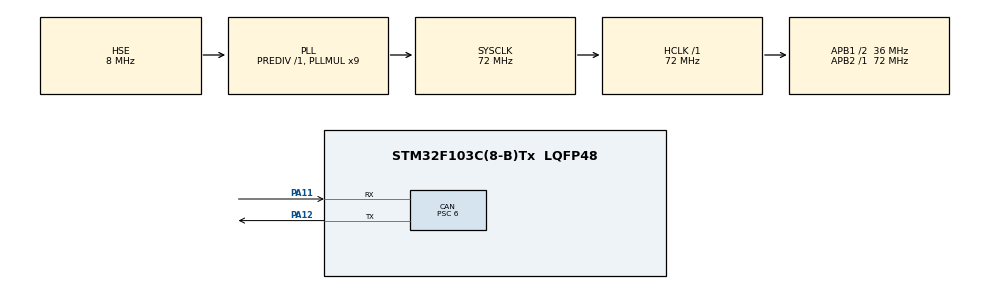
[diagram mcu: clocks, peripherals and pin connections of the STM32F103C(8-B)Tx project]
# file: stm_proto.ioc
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Mcu.Family=STM32F1
RCC.PLLSourceVirtual=RCC_PLLSOURCE_HSE
NVIC.CAN1_RX1_IRQn=true\:0\:0\:false\:true\:true\:4\:true\:true
TIM4.AutoReloadPreload=TIM_AUTORELOAD_PRELOAD_ENABLE
PD1-OSC_OUT.Mode=HSE-External-Oscillator
CAN.ABOM=ENABLE
CAN.CalculateBaudRate=500000
PA11.Mode=CAN_Activate
CAN.SJW=CAN_SJW_2TQ
PD0-OSC_IN.Signal=RCC_OSC_IN
RCC.APB1CLKDivider=RCC_HCLK_DIV2
VP_SYS_VS_ND.Mode=No_Debug
CAN.CalculateTimeBit=1999.99
TIM4.TIM_MasterOutputTrigger=TIM_TRGO_RESET
RCC.SYSCLKSource=RCC_SYSCLKSOURCE_PLLCLK
ProjectManager.StackSize=0x1000
PD1-OSC_OUT.Signal=RCC_OSC_OUT
PA12.Signal=CAN_TX
CAN.BS2=CAN_BS2_3TQ
CAN.Prescaler=6
CAN.BS1=CAN_BS1_8TQ
ProjectManager.TargetToolchain=STM32CubeIDE
RCC.HCLKFreq_Value=72000000
RCC.APB2TimFreq_Value=72000000
RCC.USBFreq_Value=72000000
TIM4.Prescaler=7200
RCC.AHBFreq_Value=72000000
PD0-OSC_IN.Mode=HSE-External-Oscillator
board=custom
RCC.PLLMUL=RCC_PLL_MUL9
RCC.APB2Freq_Value=72000000
NVIC.USB_LP_CAN1_RX0_IRQn=true\:0\:0\:false\:true\:true\:5\:true\:true
CAN.NART=ENABLE
PA8.Signal=RCC_MCO
TIM4.Period=50
Mcu.Name=STM32F103C(8-B)Tx
CAN.CalculateTimeQuantum=166.66666666666669
RCC.SYSCLKFreq_VALUE=72000000
Mcu.Package=LQFP48
PA12.Mode=CAN_Activate
PA11.Signal=CAN_RX
ProjectManager.HeapSize=0x800
VP_TIM4_VS_ClockSourceINT.Mode=Internal
NVIC.PriorityGroup=NVIC_PRIORITYGROUP_4
RCC.APB1TimFreq_Value=72000000
CAN.AWUM=ENABLE
NVIC.TIM4_IRQn=true\:1\:0\:true\:true\:true\:1\:true\:true
RCC.APB1Freq_Value=36000000
NVIC.RCC_IRQn=true\:0\:0\:false\:false\:true\:true\:false

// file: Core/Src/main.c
/* USER CODE BEGIN Header */
/**
  ******************************************************************************
  * @file           : main.c
  * @brief          : Main program body
  ******************************************************************************
  * @attention
  *
  * <h2><center>&copy; Copyright (c) 2021 STMicroelectronics.
  * All rights reserved.</center></h2>
  *
  * This software component is licensed by ST under BSD 3-Clause license,
  * the "License"; You may not use this file except in compliance with the
  * License. You may obtain a copy of the License at:
  *                        opensource.org/licenses/BSD-3-Clause
  *
  ******************************************************************************
  */
/* USER CODE END Header */
#include "main.h"

/* USER CODE BEGIN Includes */
#include "Task.h"
/* USER CODE END Includes */

CAN_HandleTypeDef hcan;

TIM_HandleTypeDef htim4;

/* USER CODE BEGIN PV */
CAN_TxHeaderTypeDef CanTxHeader;
CAN_RxHeaderTypeDef CanRxHeader;
/* USER CODE END PV */

void SystemClock_Config(void);
static void MX_GPIO_Init(void);
static void MX_CAN_Init(void);
static void MX_TIM4_Init(void);
static void MX_NVIC_Init(void);
/* USER CODE BEGIN PFP */
void CAN_Config(void);
/* USER CODE END PFP */

/* USER CODE BEGIN 0 */

void HAL_TIM_PeriodElapsedCallback(TIM_HandleTypeDef *htim)
{
	if(htim->Instance == TIM4)
	{
	    Task_Manager_IT();
	}
}

void HAL_CAN_RxFifo0FullCallback(CAN_HandleTypeDef *hcan)
{

}

void HAL_CAN_RxFifo0MsgPendingCallback(CAN_HandleTypeDef *hcan)
{
  CAN_RxHeaderTypeDef CanHeader;
  uint8_t CanRxData[8];

  HAL_CAN_GetRxMessage(hcan, CAN_RX_FIFO0, &CanHeader, CanRxData);

  if (CanHeader.IDE == CAN_ID_STD )
  {
      // Traitement des donnéess

	  OrderProcess(CanHeader.StdId, CanRxData, CanHeader.DLC);
  }
}

uint8_t cpt = 0;
/* USER CODE END 0 */

int main(void)
{
  /* USER CODE BEGIN 1 */
  unsigned char str_buff[15] ={0};

  CAN_TxHeaderTypeDef canHeader;
  unsigned char canBuff[8]={1, 2, 3, 4, 5, 6, 7, 8};
  unsigned char canMailBox;
  unsigned char * pTxMailbox=&canMailBox;
  /* USER CODE END 1 */

  /* MCU Configuration--------------------------------------------------------*/

  /* Reset of all peripherals, Initializes the Flash interface and the Systick. */
  HAL_Init();

  /* Configure the system clock */
  SystemClock_Config();

  /* Initialize all configured peripherals */
  MX_GPIO_Init();
  MX_CAN_Init();
  MX_TIM4_Init();

  /* Initialize interrupts */
  MX_NVIC_Init();
  /* USER CODE BEGIN 2 */

  /* Configure the CAN Filter */
  {
    CAN_FilterTypeDef  sFilterConfig;
    sFilterConfig.FilterBank = 0;
    sFilterConfig.FilterMode = CAN_FILTERMODE_IDMASK;
    sFilterConfig.FilterScale = CAN_FILTERSCALE_32BIT;
    sFilterConfig.FilterIdHigh = 0x0000;
    sFilterConfig.FilterIdLow = 0x0000;
    sFilterConfig.FilterMaskIdHigh = 0x0000;
    sFilterConfig.FilterMaskIdLow = 0x0000;
    sFilterConfig.FilterFIFOAssignment = CAN_RX_FIFO0;
    sFilterConfig.FilterActivation = ENABLE;
    sFilterConfig.SlaveStartFilterBank = 14;

    if (HAL_CAN_ConfigFilter(&hcan, &sFilterConfig) != HAL_OK)
    {
      /* Filter configuration Error */
      Error_Handler();
    }

    /* Activate CAN RX notification */
    if (HAL_CAN_ActivateNotification(&hcan, CAN_IT_RX_FIFO0_MSG_PENDING) != HAL_OK)
    {
      /* Notification Error */
      Error_Handler();
    }

    /* Configure Transmission process */
    canHeader.StdId = 0x321;
    canHeader.ExtId = 0x01;
    canHeader.RTR = CAN_RTR_DATA;
    canHeader.IDE = CAN_ID_STD;
    canHeader.DLC = 2;
    canHeader.TransmitGlobalTime = DISABLE;

  }
  HAL_TIM_Base_Start_IT(&htim4);

  hcan.Instance->MCR = 0x60; //IMPORTANT FOR DEBUG!!!!!!!
  TaskManager_Init();

  Light_Init();

  //HAL_CAN_WakeUp(&hcan);

  canHeader.StdId = 0x123;
  canHeader.ExtId = 0x21;
  canHeader.IDE = CAN_ID_STD;
  canHeader.RTR = CAN_RTR_DATA;
  canHeader.DLC = 4;
  canHeader.TransmitGlobalTime = DISABLE;

  HAL_CAN_AddTxMessage(&hcan, &canHeader, canBuff, pTxMailbox);

  /* USER CODE END 2 */

  /* Infinite loop */
  while (1)
  {

    /* USER CODE BEGIN 3 */
    TaskManager();
  }
  /* USER CODE END 3 */
}

void SystemClock_Config(void)
{
  RCC_OscInitTypeDef RCC_OscInitStruct = {0};
  RCC_ClkInitTypeDef RCC_ClkInitStruct = {0};

  /** Initializes the RCC Oscillators according to the specified parameters
  * in the RCC_OscInitTypeDef structure.
  */
  RCC_OscInitStruct.OscillatorType = RCC_OSCILLATORTYPE_HSE;
  RCC_OscInitStruct.HSEState = RCC_HSE_ON;
  RCC_OscInitStruct.HSEPredivValue = RCC_HSE_PREDIV_DIV1;
  RCC_OscInitStruct.HSIState = RCC_HSI_ON;
  RCC_OscInitStruct.PLL.PLLState = RCC_PLL_ON;
  RCC_OscInitStruct.PLL.PLLSource = RCC_PLLSOURCE_HSE;
  RCC_OscInitStruct.PLL.PLLMUL = RCC_PLL_MUL9;
  if (HAL_RCC_OscConfig(&RCC_OscInitStruct) != HAL_OK)
  {
    Error_Handler();
  }
  /** Initializes the CPU, AHB and APB buses clocks
  */
  RCC_ClkInitStruct.ClockType = RCC_CLOCKTYPE_HCLK|RCC_CLOCKTYPE_SYSCLK
                              |RCC_CLOCKTYPE_PCLK1|RCC_CLOCKTYPE_PCLK2;
  RCC_ClkInitStruct.SYSCLKSource = RCC_SYSCLKSOURCE_PLLCLK;
  RCC_ClkInitStruct.AHBCLKDivider = RCC_SYSCLK_DIV1;
  RCC_ClkInitStruct.APB1CLKDivider = RCC_HCLK_DIV2;
  RCC_ClkInitStruct.APB2CLKDivider = RCC_HCLK_DIV1;

  if (HAL_RCC_ClockConfig(&RCC_ClkInitStruct, FLASH_LATENCY_2) != HAL_OK)
  {
    Error_Handler();
  }
}

/**
  * @brief NVIC Configuration.
  * @retval None
  */
static void MX_NVIC_Init(void)
{
  /* TIM4_IRQn interrupt configuration */
  HAL_NVIC_SetPriority(TIM4_IRQn, 1, 0);
  HAL_NVIC_EnableIRQ(TIM4_IRQn);
  /* CAN1_RX1_IRQn interrupt configuration */
  HAL_NVIC_SetPriority(CAN1_RX1_IRQn, 0, 0);
  HAL_NVIC_EnableIRQ(CAN1_RX1_IRQn);
  /* USB_LP_CAN1_RX0_IRQn interrupt configuration */
  HAL_NVIC_SetPriority(USB_LP_CAN1_RX0_IRQn, 0, 0);
  HAL_NVIC_EnableIRQ(USB_LP_CAN1_RX0_IRQn);
}

static void MX_CAN_Init(void)
{

  hcan.Instance = CAN1;
  hcan.Init.Prescaler = 6;
  hcan.Init.Mode = CAN_MODE_NORMAL;
  hcan.Init.SyncJumpWidth = CAN_SJW_2TQ;
  hcan.Init.TimeSeg1 = CAN_BS1_8TQ;
  hcan.Init.TimeSeg2 = CAN_BS2_3TQ;
  hcan.Init.TimeTriggeredMode = DISABLE;
  hcan.Init.AutoBusOff = ENABLE;
  hcan.Init.AutoWakeUp = ENABLE;
  hcan.Init.AutoRetransmission = ENABLE;
  hcan.Init.ReceiveFifoLocked = DISABLE;
  hcan.Init.TransmitFifoPriority = DISABLE;
  if (HAL_CAN_Init(&hcan) != HAL_OK)
  {
    Error_Handler();
  }

}

static void MX_TIM4_Init(void)
{

  TIM_ClockConfigTypeDef sClockSourceConfig = {0};
  TIM_MasterConfigTypeDef sMasterConfig = {0};

  htim4.Instance = TIM4;
  htim4.Init.Prescaler = 7200;
  htim4.Init.CounterMode = TIM_COUNTERMODE_UP;
  htim4.Init.Period = 50;
  htim4.Init.ClockDivision = TIM_CLOCKDIVISION_DIV1;
  htim4.Init.AutoReloadPreload = TIM_AUTORELOAD_PRELOAD_ENABLE;
  if (HAL_TIM_Base_Init(&htim4) != HAL_OK)
  {
    Error_Handler();
  }
  sClockSourceConfig.ClockSource = TIM_CLOCKSOURCE_INTERNAL;
  if (HAL_TIM_ConfigClockSource(&htim4, &sClockSourceConfig) != HAL_OK)
  {
    Error_Handler();
  }
  sMasterConfig.MasterOutputTrigger = TIM_TRGO_RESET;
  sMasterConfig.MasterSlaveMode = TIM_MASTERSLAVEMODE_DISABLE;
  if (HAL_TIMEx_MasterConfigSynchronization(&htim4, &sMasterConfig) != HAL_OK)
  {
    Error_Handler();
  }

}

static void MX_GPIO_Init(void)
{
  GPIO_InitTypeDef GPIO_InitStruct = {0};

  /* GPIO Ports Clock Enable */
  __HAL_RCC_GPIOD_CLK_ENABLE();
  __HAL_RCC_GPIOA_CLK_ENABLE();

  /*Configure GPIO pin : PA8 */
  GPIO_InitStruct.Pin = GPIO_PIN_8;
  GPIO_InitStruct.Mode = GPIO_MODE_AF_PP;
  GPIO_InitStruct.Speed = GPIO_SPEED_FREQ_LOW;
  HAL_GPIO_Init(GPIOA, &GPIO_InitStruct);

}

/* USER CODE BEGIN 4 */
void CAN_Config(void)
{
  CAN_FilterTypeDef  sFilterConfig;

  sFilterConfig.FilterBank = 0;
  sFilterConfig.FilterMode = CAN_FILTERMODE_IDMASK;
  sFilterConfig.FilterScale = CAN_FILTERSCALE_32BIT;
  sFilterConfig.FilterIdHigh = 0x320 << 5;
  sFilterConfig.FilterIdLow = 0;
  sFilterConfig.FilterMaskIdHigh = 0xFFF << 5;
  sFilterConfig.FilterMaskIdLow = 0;
  sFilterConfig.FilterFIFOAssignment = CAN_RX_FIFO0;
  sFilterConfig.FilterActivation = DISABLE;
  sFilterConfig.SlaveStartFilterBank = 14;

  //HAL_CAN_ConfigFilter(&hcan, &sFilterConfig);

  if (HAL_CAN_ConfigFilter(&hcan, &sFilterConfig) != HAL_OK)
   {
   /* Filter configuration Error */
   Error_Handler();
   }

  HAL_CAN_Start(&hcan);

  HAL_CAN_ActivateNotification(&hcan, CAN_IT_RX_FIFO0_MSG_PENDING);
  HAL_CAN_ActivateNotification(&hcan, CAN_IT_RX_FIFO0_FULL);

  HAL_CAN_ActivateNotification(&hcan, CAN_IT_RX_FIFO1_MSG_PENDING);
  HAL_CAN_ActivateNotification(&hcan, CAN_IT_RX_FIFO1_FULL);

  CanTxHeader.StdId = 0x320;
  CanTxHeader.ExtId = 0x01;
  CanTxHeader.RTR = CAN_RTR_DATA;
  CanTxHeader.IDE = CAN_ID_STD;
  CanTxHeader.DLC = 2;
  CanTxHeader.TransmitGlobalTime = DISABLE;
}
/* USER CODE END 4 */

void Error_Handler(void)
{
  __disable_irq();
  while (1)
  {
  }
}

/************************ (C) COPYRIGHT STMicroelectronics *****END OF FILE****/
